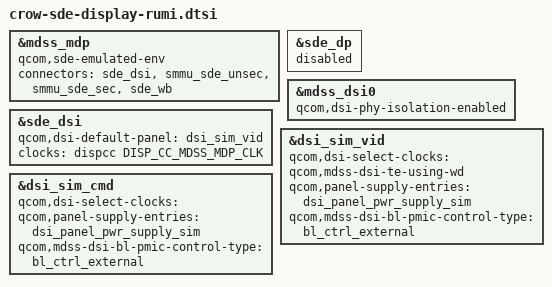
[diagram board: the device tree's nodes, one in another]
#include "crow-sde-display.dtsi"

&mdss_mdp {
	qcom,sde-emulated-env;
	connectors = <&sde_dsi &smmu_sde_unsec &smmu_sde_sec &sde_wb>;
};

&sde_dp {
	status="disabled";
};
&mdss_dsi0 {
	qcom,dsi-phy-isolation-enabled;
};

&sde_dsi {
	qcom,dsi-default-panel = <&dsi_sim_vid>;
	clocks = <&dispcc DISP_CC_MDSS_MDP_CLK>;
	clock-names = "mdp_core_clk";
};

&dsi_sim_vid {
	qcom,dsi-select-clocks = "";
	qcom,mdss-dsi-te-using-wd;
	qcom,panel-supply-entries = <&dsi_panel_pwr_supply_sim>;
	qcom,mdss-dsi-bl-pmic-control-type = "bl_ctrl_external";
};

&dsi_sim_cmd {
	qcom,dsi-select-clocks = "";
	/delete-property/ qcom,mdss-dsi-lane-3-state;
	/delete-property/ qcom,poms-align-panel-vsync;
	qcom,panel-supply-entries = <&dsi_panel_pwr_supply_sim>;
	qcom,mdss-dsi-bl-pmic-control-type = "bl_ctrl_external";
};
